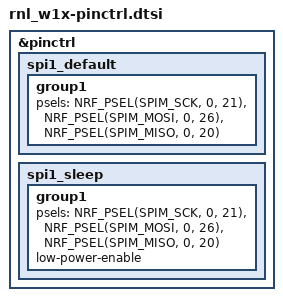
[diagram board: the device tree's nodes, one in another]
/*
 * Copyright (c) 2023 RedNodeLabs.
 * SPDX-License-Identifier: Apache-2.0
 */

&pinctrl {
	spi1_default: spi1_default {
		group1 {
			psels = <NRF_PSEL(SPIM_SCK, 0, 21)>,
				<NRF_PSEL(SPIM_MOSI, 0, 26)>,
				<NRF_PSEL(SPIM_MISO, 0, 20)>;
		};
	};

	spi1_sleep: spi1_sleep {
		group1 {
			psels = <NRF_PSEL(SPIM_SCK, 0, 21)>,
				<NRF_PSEL(SPIM_MOSI, 0, 26)>,
				<NRF_PSEL(SPIM_MISO, 0, 20)>;
			low-power-enable;
		};
	};
};
